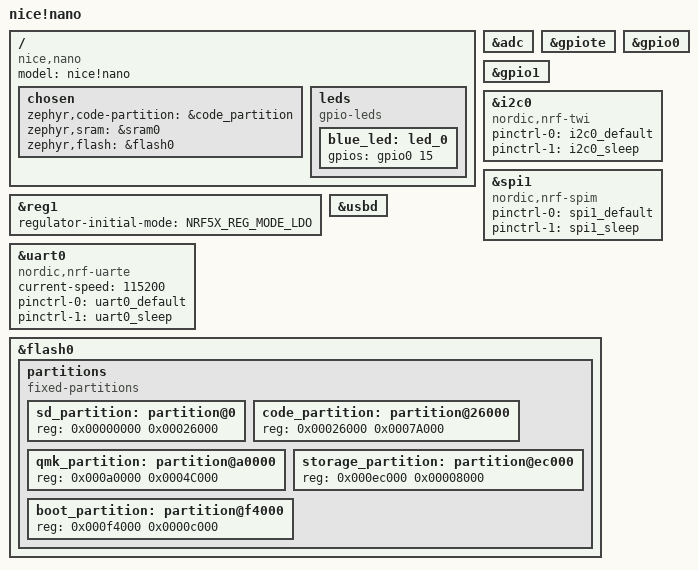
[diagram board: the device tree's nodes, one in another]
/*
 * Copyright (c) 2021 The ZMK Contributors
 *
 * SPDX-License-Identifier: MIT
 */

/dts-v1/;

#include <nordic/nrf52840_qiaa.dtsi>
#include "nice_nano-pinctrl.dtsi"
#include <common/nordic/nrf52840_uf2_boot_mode.dtsi>


/ {
    model = "nice!nano";
    compatible = "nice,nano";

    chosen {
        zephyr,code-partition = &code_partition;
        zephyr,sram = &sram0;
        zephyr,flash = &flash0;
    };

    leds {
        compatible = "gpio-leds";
        blue_led: led_0 {
            gpios = <&gpio0 15 GPIO_ACTIVE_HIGH>;
        };
    };
};

&reg1 {
    regulator-initial-mode = <NRF5X_REG_MODE_LDO>;
};

&adc {
    status = "okay";
};

&gpiote {
    status = "okay";
};

&gpio0 {
    status = "okay";
};

&gpio1 {
    status = "okay";
};

&i2c0 {
    compatible = "nordic,nrf-twi";
    pinctrl-0 = <&i2c0_default>;
    pinctrl-1 = <&i2c0_sleep>;
    pinctrl-names = "default", "sleep";
};

&spi1 {
    compatible = "nordic,nrf-spim";
    pinctrl-0 = <&spi1_default>;
    pinctrl-1 = <&spi1_sleep>;
    pinctrl-names = "default", "sleep";
};

&uart0 {
    compatible = "nordic,nrf-uarte";
    current-speed = <115200>;
    pinctrl-0 = <&uart0_default>;
    pinctrl-1 = <&uart0_sleep>;
    pinctrl-names = "default", "sleep";
};

zephyr_udc0: &usbd {
    status = "okay";
};


&flash0 {
    /*
     * For more information, see:
     * http://docs.zephyrproject.org/latest/devices/dts/flash_partitions.html
     */
    partitions {
        compatible = "fixed-partitions";
        #address-cells = <1>;
        #size-cells = <1>;

        sd_partition: partition@0 {
            reg = <0x00000000 0x00026000>;
        };

        /*
         *  给 ZMK app 使用 488kb 
         */
        code_partition: partition@26000 {
            reg = <0x00026000 0x0007A000>;//152->640 (488kb)
        };

        /*
            给qmk使用304kb 大小的分区
        */
        qmk_partition: partition@a0000 {
            reg = <0x000a0000 0x0004C000>;  //640K -> 944K (304kb)
        };

        /*
         * zmk 存储使用
         */
        storage_partition: partition@ec000 {
            reg = <0x000ec000 0x00008000>;//944K -> 976kb (32kb)
        };

        //bootloader 使用
        boot_partition: partition@f4000 {
            reg = <0x000f4000 0x0000c000>;//976kb -> 1024kb (48kb)
        };
    };
};
